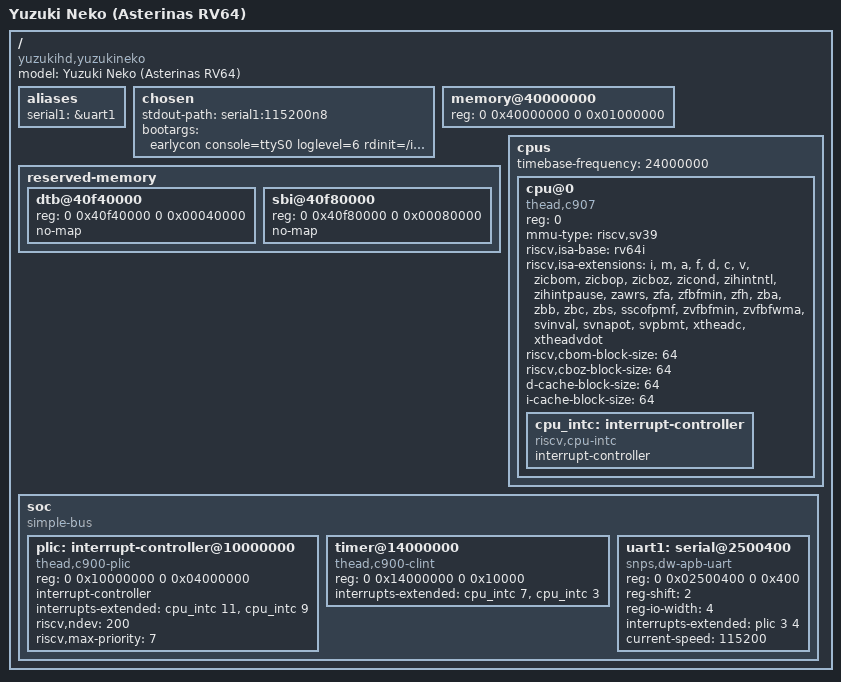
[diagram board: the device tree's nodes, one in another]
// SPDX-License-Identifier: MPL-2.0

/dts-v1/;

/*
 * Minimal S-mode DT for the RV64 F101S3 loader. Hardware values follow:
 * https://github.com/YuzukiHD/linux-mainline/tree/735f2ca14b7b916b17fa111a941a9a79d0c12e61/arch/riscv/boot/dts/allwinner
 * Firmware initializes PSRAM, UART1 clocks/pins, caches and PLIC delegation.
 */
/ {
    model = "Yuzuki Neko (Asterinas RV64)";
    compatible = "yuzukihd,yuzukineko", "allwinner,sun252i-f101";
    #address-cells = <2>;
    #size-cells = <2>;

    aliases {
        serial1 = &uart1;
    };

    chosen {
        stdout-path = "serial1:115200n8";
        bootargs = "earlycon console=ttyS0 loglevel=6 rdinit=/init";
        /* The image builder adds linux,initrd-start/end for an initramfs. */
    };

    memory@40000000 {
        device_type = "memory";
        reg = <0 0x40000000 0 0x01000000>;
    };

    reserved-memory {
        #address-cells = <2>;
        #size-cells = <2>;
        ranges;

        dtb@40f40000 {
            reg = <0 0x40f40000 0 0x00040000>;
            no-map;
        };

        sbi@40f80000 {
            reg = <0 0x40f80000 0 0x00080000>;
            no-map;
        };
    };

    cpus {
        #address-cells = <1>;
        #size-cells = <0>;
        timebase-frequency = <24000000>;

        cpu@0 {
            compatible = "thead,c907", "riscv";
            device_type = "cpu";
            reg = <0>;
            status = "okay";
            mmu-type = "riscv,sv39";
            riscv,isa-base = "rv64i";
            riscv,isa-extensions = "i", "m", "a", "f", "d", "c", "v",
                "zicbom", "zicbop", "zicboz", "zicond", "zihintntl",
                "zihintpause", "zawrs", "zfa", "zfbfmin", "zfh", "zba",
                "zbb", "zbc", "zbs", "sscofpmf", "zvfbfmin", "zvfbfwma",
                "svinval", "svnapot", "svpbmt", "xtheadc", "xtheadvdot";
            riscv,cbom-block-size = <64>;
            riscv,cboz-block-size = <64>;
            d-cache-block-size = <64>;
            i-cache-block-size = <64>;

            cpu_intc: interrupt-controller {
                compatible = "riscv,cpu-intc";
                interrupt-controller;
                #interrupt-cells = <1>;
                #address-cells = <0>;
            };
        };
    };

    soc {
        compatible = "simple-bus";
        #address-cells = <2>;
        #size-cells = <2>;
        ranges;

        plic: interrupt-controller@10000000 {
            compatible = "thead,c900-plic";
            reg = <0 0x10000000 0 0x04000000>;
            interrupt-controller;
            #address-cells = <0>;
            #interrupt-cells = <2>;
            interrupts-extended = <&cpu_intc 11>, <&cpu_intc 9>;
            riscv,ndev = <200>;
            riscv,max-priority = <7>;
        };

        timer@14000000 {
            compatible = "thead,c900-clint";
            reg = <0 0x14000000 0 0x10000>;
            interrupts-extended = <&cpu_intc 7>, <&cpu_intc 3>;
        };

        uart1: serial@2500400 {
            compatible = "snps,dw-apb-uart";
            reg = <0 0x02500400 0 0x400>;
            reg-shift = <2>;
            reg-io-width = <4>;
            interrupts-extended = <&plic 3 4>;
            current-speed = <115200>;
            status = "okay";
        };
    };
};
